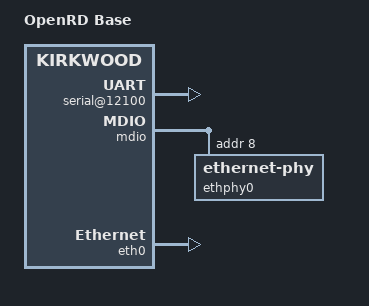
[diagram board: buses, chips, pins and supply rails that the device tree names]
/dts-v1/;
#include "kirkwood-openrd.dtsi"
/ {
	model = "OpenRD Base";
	compatible = "marvell,openrd-base", "marvell,openrd", "marvell,kirkwood-88f6281", "marvell,kirkwood";
	ocp@f1000000 {
		serial@12100 {
			status = "okay";
		};
	};
};
&mdio {
	status = "okay";
	ethphy0: ethernet-phy@8 {
		reg = <8>;
	};
};
&eth0 {
	status = "okay";
	ethernet0-port@0 {
		phy-handle = <&ethphy0>;
	};
};
